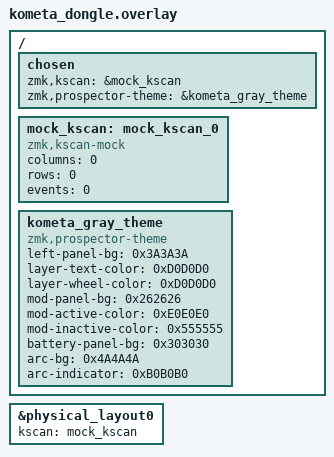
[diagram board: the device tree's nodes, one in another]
#include "kometa.dtsi"

// The dongle has no keys of its own: replace the matrix with a mock kscan.
/ {
    chosen {
        zmk,kscan = &mock_kscan;
    };

    mock_kscan: mock_kscan_0 {
        compatible = "zmk,kscan-mock";
        columns = <0>;
        rows = <0>;
        events = <0>;
    };
};

&physical_layout0 {
    kscan = <&mock_kscan>;
};

/delete-node/ &kscan0;

// Prospector "Radii" theme: dark gray, no blue
/ {
    chosen {
        zmk,prospector-theme = &kometa_gray_theme;
    };

    kometa_gray_theme: kometa_gray_theme {
        compatible = "zmk,prospector-theme";
        left-panel-bg = <0x3A3A3A>;
        layer-text-color = <0xD0D0D0>;
        layer-wheel-color = <0xD0D0D0>;
        mod-panel-bg = <0x262626>;
        mod-active-color = <0xE0E0E0>;
        mod-inactive-color = <0x555555>;
        battery-panel-bg = <0x303030>;
        arc-bg = <0x4A4A4A>;
        arc-indicator = <0xB0B0B0>;
    };
};
